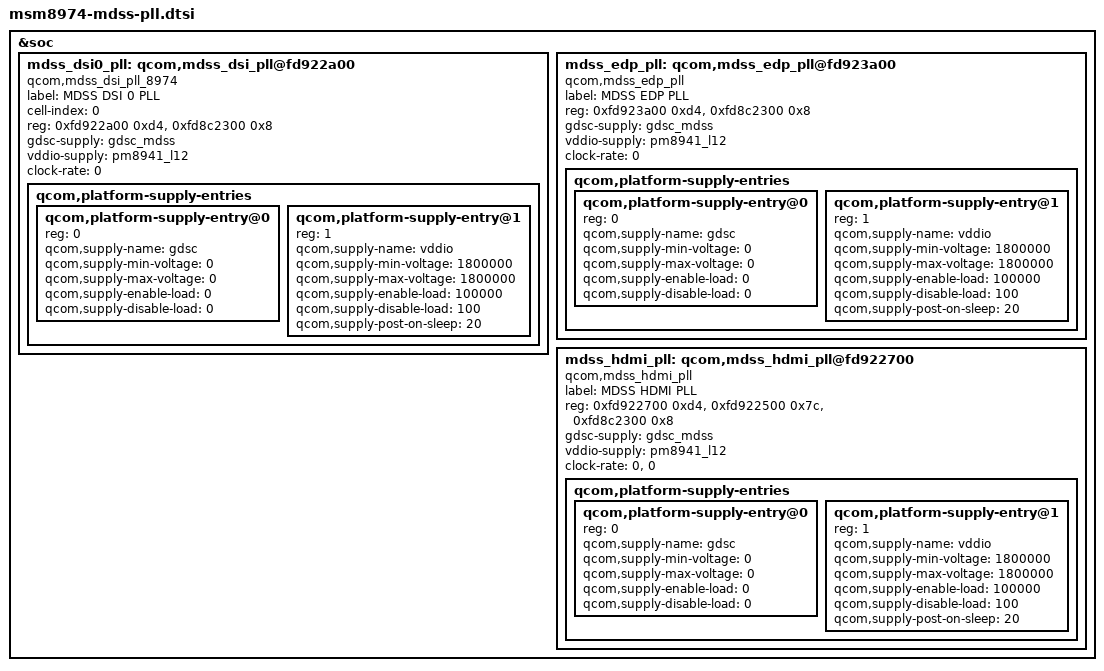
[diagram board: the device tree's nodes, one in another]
/* Copyright (c) 2014, The Linux Foundation. All rights reserved.
 *
 * This program is free software; you can redistribute it and/or modify
 * it under the terms of the GNU General Public License version 2 and
 * only version 2 as published by the Free Software Foundation.
 *
 * This program is distributed in the hope that it will be useful,
 * but WITHOUT ANY WARRANTY; without even the implied warranty of
 * MERCHANTABILITY or FITNESS FOR A PARTICULAR PURPOSE.  See the
 * GNU General Public License for more details.
 */

&soc {
	mdss_dsi0_pll: qcom,mdss_dsi_pll@fd922a00 {
		compatible = "qcom,mdss_dsi_pll_8974";
		label = "MDSS DSI 0 PLL";
		cell-index = <0>;

		reg = <0xfd922a00 0xd4>,
		      <0xfd8c2300 0x8>;
		reg-names = "pll_base", "gdsc_base";

		gdsc-supply = <&gdsc_mdss>;
		vddio-supply = <&pm8941_l12>;

		clock-names = "iface_clk";
		clock-rate = <0>;

		qcom,platform-supply-entries {
			#address-cells = <1>;
			#size-cells = <0>;

			qcom,platform-supply-entry@0 {
				reg = <0>;
				qcom,supply-name = "gdsc";
				qcom,supply-min-voltage = <0>;
				qcom,supply-max-voltage = <0>;
				qcom,supply-enable-load = <0>;
				qcom,supply-disable-load = <0>;
			};

			qcom,platform-supply-entry@1 {
				reg = <1>;
				qcom,supply-name = "vddio";
				qcom,supply-min-voltage = <1800000>;
				qcom,supply-max-voltage = <1800000>;
				qcom,supply-enable-load = <100000>;
				qcom,supply-disable-load = <100>;
				qcom,supply-post-on-sleep = <20>;
			};
		};
	};

	mdss_edp_pll: qcom,mdss_edp_pll@fd923a00 {
		compatible = "qcom,mdss_edp_pll";
		label = "MDSS EDP PLL";

		reg = <0xfd923a00 0xd4>,
		      <0xfd8c2300 0x8>;
		reg-names = "pll_base", "gdsc_base";

		gdsc-supply = <&gdsc_mdss>;
		vddio-supply = <&pm8941_l12>;

		clock-names = "iface_clk";
		clock-rate = <0>;

		qcom,platform-supply-entries {
			#address-cells = <1>;
			#size-cells = <0>;

			qcom,platform-supply-entry@0 {
				reg = <0>;
				qcom,supply-name = "gdsc";
				qcom,supply-min-voltage = <0>;
				qcom,supply-max-voltage = <0>;
				qcom,supply-enable-load = <0>;
				qcom,supply-disable-load = <0>;
			};

			qcom,platform-supply-entry@1 {
				reg = <1>;
				qcom,supply-name = "vddio";
				qcom,supply-min-voltage = <1800000>;
				qcom,supply-max-voltage = <1800000>;
				qcom,supply-enable-load = <100000>;
				qcom,supply-disable-load = <100>;
				qcom,supply-post-on-sleep = <20>;
			};
		};
	};

	mdss_hdmi_pll: qcom,mdss_hdmi_pll@fd922700 {
		compatible = "qcom,mdss_hdmi_pll";
		label = "MDSS HDMI PLL";

		reg = <0xfd922700 0xd4>,
		      <0xfd922500 0x7c>,
		      <0xfd8c2300 0x8>;
		reg-names = "pll_base", "phy_base", "gdsc_base";

		gdsc-supply = <&gdsc_mdss>;
		vddio-supply = <&pm8941_l12>;

		clock-names = "iface_clk", "alt_iface_clk";
		clock-rate = <0>, <0>;

		qcom,platform-supply-entries {
			#address-cells = <1>;
			#size-cells = <0>;

			qcom,platform-supply-entry@0 {
				reg = <0>;
				qcom,supply-name = "gdsc";
				qcom,supply-min-voltage = <0>;
				qcom,supply-max-voltage = <0>;
				qcom,supply-enable-load = <0>;
				qcom,supply-disable-load = <0>;
			};

			qcom,platform-supply-entry@1 {
				reg = <1>;
				qcom,supply-name = "vddio";
				qcom,supply-min-voltage = <1800000>;
				qcom,supply-max-voltage = <1800000>;
				qcom,supply-enable-load = <100000>;
				qcom,supply-disable-load = <100>;
				qcom,supply-post-on-sleep = <20>;
			};
		};
	};
};
